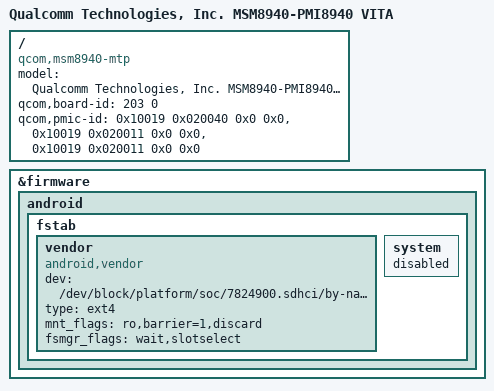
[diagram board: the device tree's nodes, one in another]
/*
 * Copyright (c) 2016, The Linux Foundation. All rights reserved.
 *
 * This program is free software; you can redistribute it and/or modify
 * it under the terms of the GNU General Public License version 2 and
 * only version 2 as published by the Free Software Foundation.
 *
 * This program is distributed in the hope that it will be useful,
 * but WITHOUT ANY WARRANTY; without even the implied warranty of
 * MERCHANTABILITY or FITNESS FOR A PARTICULAR PURPOSE.  See the
 * GNU General Public License for more details.
 */

/dts-v1/;

#include "msm8940.dtsi"
#include "msm8940-pmi8940-mtp.dtsi"
#include "zte-msm8940-pmi8940-vita.dtsi"

/ {
	model = "Qualcomm Technologies, Inc. MSM8940-PMI8940 VITA";
	compatible = "qcom,msm8940-mtp", "qcom,msm8940", "qcom,mtp";
	qcom,board-id= <203 0>;
	qcom,pmic-id = <0x10019 0x020040 0x0 0x0>, <0x10019 0x020011 0x0 0x0>, <0x10019 0x020011 0x0 0x0>;
};

/*zte add by chenwei10196163 for P840F10 compatible with Android N start. by yuanlin for AB */
&firmware {
	android {
		fstab {
			vendor {
				compatible = "android,vendor";
				dev = "/dev/block/platform/soc/7824900.sdhci/by-name/vendor";
				type = "ext4";
				mnt_flags = "ro,barrier=1,discard";
				fsmgr_flags = "wait,slotselect";
				status = "ok";
			};
			system {
				status = "disabled";
			};
		};
	};
};
/*zte add by chenwei10196163 for P840F10 compatible with Android N end*/

